# RL6678_IP_SVD register map
Vendor: Realtek
Registers are 32-bit, read-write, reset 0x0 unless marked. A register's access mark holds for its fields unless they carry their own. Offsets are from the block's base; [hi:lo] are bit positions; {n}, {i} and the like mark numbered series.

## LP_SYS
Base 0x42008200
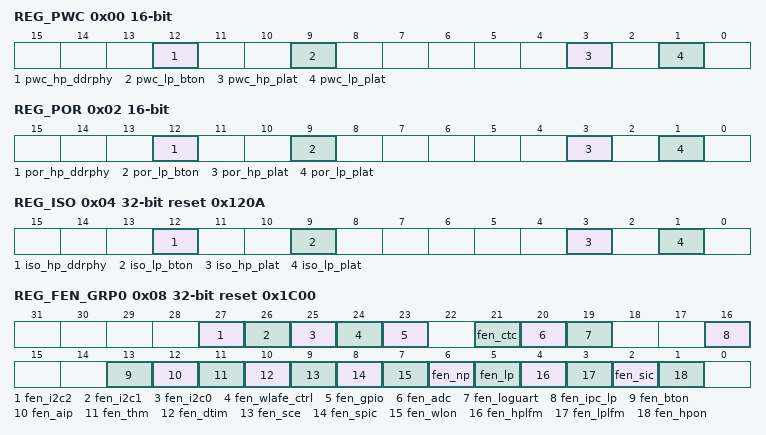
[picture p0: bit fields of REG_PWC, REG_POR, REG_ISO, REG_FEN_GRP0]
0x00 REG_PWC 16-bit
  [12] pwc_hp_ddrphy — 1: Enable ddr phy core power cut 0: Disable
  [9] pwc_lp_bton — This is BT function total power cut control , the BT off power cut is follow it , and is controlled by BT IP . 1: Enable BT power cut 0: Disable
  [3] pwc_hp_plat — This is the default power dommain. 1: Enable HP plat power cut 0: Disable
  [1] pwc_lp_plat — 1: Enable Lp plat power cut 0: Disable
0x02 REG_POR 16-bit
  [12] por_hp_ddrphy — 0: global reset PD_HP_DDRPHY power domain 1: release reset
  [9] por_lp_bton — 0: global reset PD_LP_BTON power domain 1: release por
  [3] por_hp_plat — 0: global reset PD_HP_PLFM power domain 1: release por
  [1] por_lp_plat — 0: global reset PD_LP_PLAT power domain 1: release por
0x04 REG_ISO reset 0x120A
  [12] iso_hp_ddrphy — 1: isolate signals from PD_HP_DDRPHY to other power domain 0: release iso
  [9] iso_lp_bton — 1: isolate signals from PD_LP_BTON to other power domain 0: release iso
  [3] iso_hp_plat — 1: isolate signals from PD_HP_PLFM to other power domain 0: release iso
  [1] iso_lp_plat — 1: isolate signals from PD_LP_PLAT to other power domain 0: release iso
0x08 REG_FEN_GRP0 reset 0x1C00
  [27] fen_i2c2 — 1: enable HS I2C1 function 0: reset
  [26] fen_i2c1 — 1: enable HS I2C0 function 0: reset
  [25] fen_i2c0 — 1: enable LS I2C function 0: reset
  [24] fen_wlafe_ctrl — 1: enable WL RFAFE control circuit, shall be 1 when enable WL or BT use WL RFAFE 0: reset
  [23] fen_gpio — 1: enable LS GPIO function 0: reset
  [21] fen_ctc — 1: enable Captouch ADC function 0: reset
  [20] fen_adc — 1: enable LS ADC function 0: reset
  [19] fen_loguart — Uartlog function reset 1: enable 0: reset
  [16] fen_ipc_lp — 1: enable LS IPC function 0: reset
  [13] fen_bton — BTON function enable 1: enable 0: disable
  [12] fen_aip — Debug thermal function enable
  [11] fen_thm — Debug thermal function enable
  [10] fen_dtim — Debug timer function enable
  [9] fen_sce — Flash sce function enable 1: enable sce 0: disable
  [8] fen_spic — Flash spic function enable 1: enable flash 0: disable flash
  [7] fen_wlon — WLON function enable 1: enable 0: disable
  [6] fen_np — 1: enable KM4 0: reset
  [5] fen_lp — 1: enable KM0 0: reset
  [4] fen_hplfm — 1: enable HP platform 0: reset
  [3] fen_lplfm — 1: enable LP platform 0: reset
  [2] fen_sic — 1: enable SIC function 0: reset
  [1] fen_hpon — 1: enable HS SYSON Function 0: reset
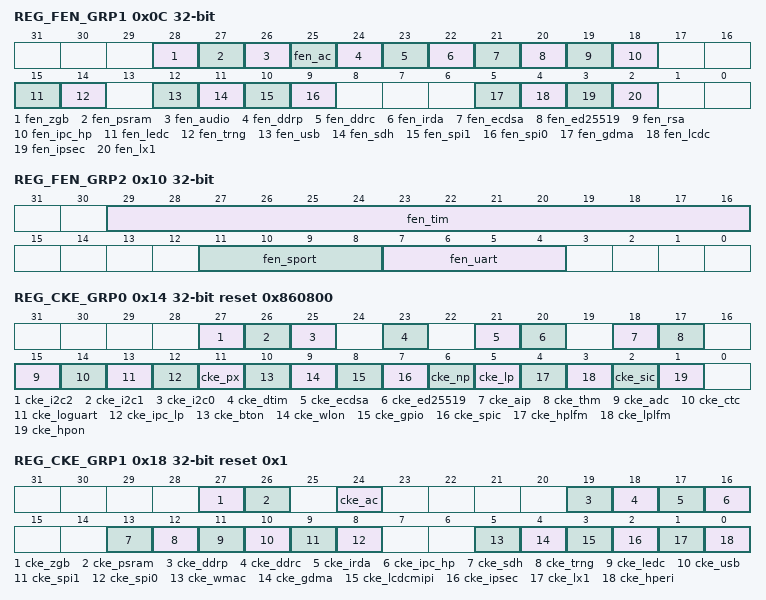
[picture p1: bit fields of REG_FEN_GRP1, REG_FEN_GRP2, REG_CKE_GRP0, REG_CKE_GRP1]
0x0C REG_FEN_GRP1
  [28] fen_zgb — 1: enable zgb function 0: disable Note: for zgb is in wlan off domain , after turn wlan off , it need an 0->1 transiton
  [27] fen_psram — 1: enable PSRAM function 0: disable
  [26] fen_audio — When audio function enable , HS_SYSON_RAM domain must be on , for HSRAM memory at least in retention mode . 1: enable audio function 0: disable
  [25] fen_ac — 1: enable audio codec active function 0: disable
  [24] fen_ddrp — 1: enable ddr phy function 0: disable
  [23] fen_ddrc — 1: enable ddr controller function 0: disable
  [22] fen_irda — 1: enable girda function 0: disable
  [21] fen_ecdsa — 1: enable ecdsa function 0: disable
  [20] fen_ed25519 — 1: enable ed25519 function 0: disable
  [19] fen_rsa — 1: enable rsa function 0: disable
  [18] fen_ipc_hp — 1: enable IPC function 0: disable
  [15] fen_ledc — 1: enable SPORT function 0: disable
  [14] fen_trng — 1: enable TRNG function 0: disable
  [12] fen_usb — 1: enable USB function 0: disable
  [11] fen_sdh — 1: enable SDH function 0: disable
  [10] fen_spi1 — 1: enable SPI1 function 0: disable
  [9] fen_spi0 — 1: enable SPI0 function 0: disable
  [5] fen_gdma — 1: enable GDMA0 function 0: disable
  [4] fen_lcdc — 1: enable LCDC function 0: disable
  [3] fen_ipsec — 1: enable IPSEC function 0: disable
  [2] fen_lx1 — 1: enable LX1 system function 0: disable
0x10 REG_FEN_GRP2
  [29:16] fen_tim — Timer0-13 function enable 0-7 : lp basic timer 8 : pwm timer 9: pulse timer 13-10 : hp basic timer
  [11:8] fen_sport — 1: enable SPORT function 0: disable
  [7:4] fen_uart — Uart function reset (Note uart3 if for BT)
0x14 REG_CKE_GRP0 reset 0x860800
  [27] cke_i2c2 — 1: Enable HS I2C1 clock
  [26] cke_i2c1 — 1: Enable HS I2C0 clock
  [25] cke_i2c0 — 1: Enable LS I2C clock
  [23] cke_dtim — 1: Enable LS dtim clk
  [21] cke_ecdsa — 1: Enable ecdsa engine clock
  [20] cke_ed25519 — 1: Enable ed25519 engine clock
  [18] cke_aip — 1: Enable apb clk for aip use , include xtal/pll/regu control
  [17] cke_thm — 1: Enable LS thm clock
  [15] cke_adc — 1: Enable LS ADC clock
  [14] cke_ctc — 1: Enable Captouch clock
  [13] cke_loguart — 1: Enable Uartlog clock
  [12] cke_ipc_lp — 1: Enable LS IPC clock
  [11] cke_px — 1: Enable Pinmux clock
  [10] cke_bton — 1: Enable BT AON clock
  [9] cke_wlon — 1: Enable WLAN AON clock
  [8] cke_gpio — 1: Enable GPIO clock
  [7] cke_spic — 1: Enable SPIC source clock
  [6] cke_np — 1: Enable KM4 clock
  [5] cke_lp — 1: Enable KM0 clock
  [4] cke_hplfm — 1: Enable hs platform clock
  [3] cke_lplfm — 1: Enable ls platform clock
  [2] cke_sic — 1: Enable SIC clock
  [1] cke_hpon — 1: Enable HSYSON register clock; 0: gated SYSON Register clock
0x18 REG_CKE_GRP1 reset 0x1
  [27] cke_zgb — 1: Enable zgb bus clock 0: Disable
  [26] cke_psram — 1: Enable PSRAM bus clock 0: Disable
  [24] cke_ac — 1: Enable audio codec clock 0: Disable
  [19] cke_ddrp — 1: Enable ddr phy clock 0: Disable
  [18] cke_ddrc — 1: Enable ddrc clock 0: Disable
  [17] cke_irda — 1: Enable irda clock 0: Disable
  [16] cke_ipc_hp — 1: Enable IPC clock 0: Disable
  [13] cke_sdh — 1: Enable SD HOST bus clock 0: Disable
  [12] cke_trng — 1: Enable trng bus clock 0: Disable
  [11] cke_ledc — 1: Enable ledc bus clock 0: Disable
  [10] cke_usb — 1: Enable USB bus clock 0: Disable
  [9] cke_spi1 — 1: Enable SPI1 clock 0: Disable
  [8] cke_spi0 — 1: Enable SPI0 clock 0: Disable
  [5] cke_wmac
  [4] cke_gdma — 1: Enable GDMA0 clock 0: Disable
  [3] cke_lcdcmipi — 1: Enable LCDC&MIPI clock 0: Disable
  [2] cke_ipsec — 1: Enable ipsec clock 0: Disable
  [1] cke_lx1 — 1: Enable lx1 bus clock 0: Disable
  [0] cke_hperi — 1: Enable hperi clock . If IP using hperi clk , this bit must be set . 0: Disable
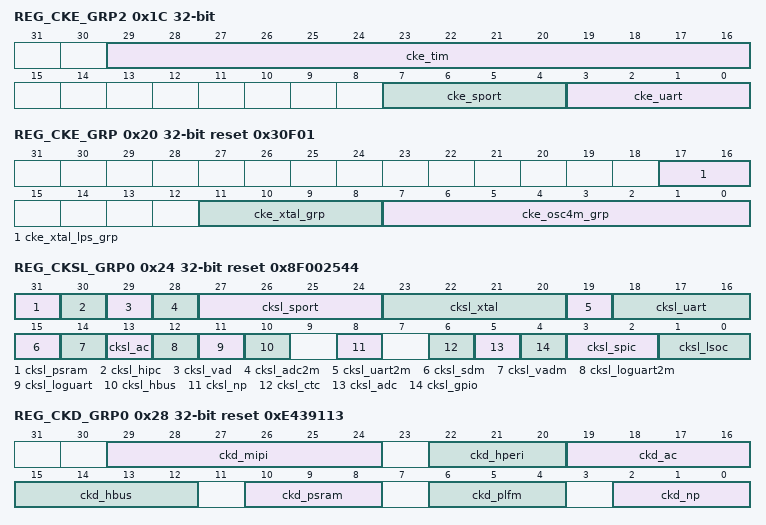
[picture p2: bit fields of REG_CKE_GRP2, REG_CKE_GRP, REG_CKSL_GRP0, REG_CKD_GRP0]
0x1C REG_CKE_GRP2
  [29:16] cke_tim — Timer0-13 clock enable 0-7 : lp basic timer 8 : pwm timer 9: pulse timer 13-10 : hp basic timer
  [7:4] cke_sport — 1: Enable 4path sport clock 0: Disable
  [3:0] cke_uart — 1: Enable Uart1 clock 0: Disable
0x20 REG_CKE_GRP reset 0x30F01
  [17:16] cke_xtal_lps_grp — XTAL lps clock(312.5K) for different use , when neither func used . [0]: system SDM 32K [1]: bt lps clk Note : This field only used for HW debug , software needn't to config it for normal function.
  [11:8] cke_xtal_grp — XTAL 40M clock used for different use , when neither func used [0]: LP system [1]: 40M peri [2]: 2M peri [3]: 40M for NP when xtal is in LPS mode Note : This field only used for HW debug , software needn't to config it for normal function.
  [7:0] cke_osc4m_grp — OSC4M used for different use , when neither func used , osc4m can be disabled . 0: LP system 4M 1: OSC2M peri 2: WL/BT common 3: WL ana clock 4: BT ana clock 5: SDH ana clock 6: aip func control 7: vad Note : This field only used for HW debug , software needn't to config it for normal function. Not use, move to aon reg: cke_osc4m_force
0x24 REG_CKSL_GRP0 reset 0x8F002544
  [31] cksl_psram — psram phy clock seleck 0: xtal 40M 1: nppll divided clock , max to 300M
  [30] cksl_hipc — hs_ipc clock select 0: hapb clk 1: lpon clk(4M)
  [29] cksl_vad — audio codec vad clock select 0: osc4m output 1: xtal 40M divider 10 output . Note : make xtal enter lps mode when vad work to save power
  [28] cksl_adc2m — ADC 2M seleck 0: osc4M divider 2 1: xtal 40M divider out
  [27:24] cksl_sport — sport clock selection 0: equal to audio codec main clock (40M) 1: from I2S pll , after i2s pll selection and divider
  [23:20] cksl_xtal — xtal selection, Default=40MHz 0000: 40MHz 0001: 25MHz 0010: 13MHz 0011: 19.2MHz 0100: 20MHz 0101: 26MHz 0110: 38.4MHz 0111: 17.664MHz 1000: 16MHz 1001: 14.138MHz 1010: 12MHz 1011: 52MHz 1100: 48MHz 1101: 27MHz 1110: 24MHz 1111: none
  [19] cksl_uart2m — Uart 2M seleck 0: osc4M divider 2 1: xtal 40M divider out
  [18:16] cksl_uart — Select uart rx clock for every uart . (Note uart3 is BT uart , always 40M) 0: rx clock is xtal 40M 1: rx clock is 2M (osc2M or xtal divided 2M)
  [15] cksl_sdm — sdm 128 clock select , this must be fixed after initial selection. 0:osc128 1:xtal lps 312.5K
  [14] cksl_vadm — vad share memory clock select . Note, it must first change this bit to 1,and then shutdown hs plfm . When wakeup , it must first enable hs plfm , finally set this bit to 0 . 0: used by hs plfm clock 1: used by vad buffer ctrol
  [13] cksl_ac — audio codec main clock selection 0: syspll divided 40M 1: xtal 40M
  [12] cksl_loguart2m — Loguart 2M seleck 0: osc4M divider 2 1: xtal 40M divider out
  [11] cksl_loguart — Select loguart trx clock 0: clock is xtal 40M 1: clock is 2M
  [10] cksl_hbus — HP bus clock seletion 1: from nppll divider output , which default is 100M 0: from xtal 40M clock
  [8] cksl_np — NP(KM4) clock seletion 1: from nppll divider output , which default is 320M 0: from xtal 40M clock
  [6] cksl_ctc — CTC REG clock selection 0: 131k 1: LS APB Clock
  [5] cksl_adc — ADC INT clock selection 0: LS APB clock 1: OSC2M
  [4] cksl_gpio — GPIO INT clock selecton: 0: LS APB clock 1: 32.768K clock from SDM
  [3:2] cksl_spic — SPIC clock sel: 00/10: OSC4M 01: XTAL 40M 11: nppll divided out,max to 200M
  [1:0] cksl_lsoc — KM0 cpu clock seletion 2'b00/2'b01: ANA4M 2'b10/2'b11: XTAL
0x28 REG_CKD_GRP0 reset 0xE439113
  [29:24] ckd_mipi — mipi vo clock divider, it is based on nppll clock Max timing signoff clock is 66.7M . Default is 800/12 = 66.7 divider by this value + 1
  [22:20] ckd_hperi — audio main clock divider, it is based on np pll output 0~2 : not valid 3: div4 4: div5 other: divider by this value + 1
  [19:16] ckd_ac — audio main clock divider, it is based on np pll output 0~2 : not valid 3: div20 4: div21 other: divider by this value + 17
  [15:12] ckd_hbus — ahb clock divider, it is based on np pll output 0~6 : not valid 7: div8 8: div9 other: divider by this value + 1
  [10:8] ckd_psram — PSRAM phy clock divider, it is based on np pll (600M). 0: not valid 1: div2 2: div3 3/other: divider by this value + 1
  [6:4] ckd_plfm — PLFM clock divider, it is based on np clock . 0: not valid 1: div2 (it is better to fix in this value) 2: div3 3/other: divider by this value + 1
  [2:0] ckd_np — NP clock divider, it is based on np pll (800M). 0: not valid 1: div2 2: div3 3/other: divider by this value + 1
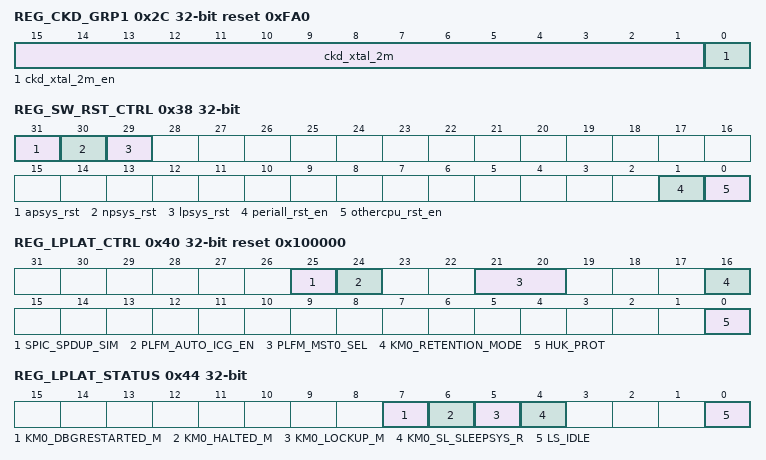
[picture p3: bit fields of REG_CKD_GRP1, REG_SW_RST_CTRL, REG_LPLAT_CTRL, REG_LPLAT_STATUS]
0x2C REG_CKD_GRP1 reset 0xFA0
  [15:1] ckd_xtal_2m — Output divided clock frequency for UART: BIT_LSYS_UART_XTAL_DIV_FREQ/1000 (MHz)
  [0] ckd_xtal_2m_en — 1: enable XTAL division circuit for UART
0x38 REG_SW_RST_CTRL
  [31] apsys_rst — Only when REG_SW_RST_TRIG is 0x69696969 , this reg can be write
  [30] npsys_rst — Only when REG_SW_RST_TRIG is 0x69696969 , this reg can be write
  [29] lpsys_rst — Only when REG_SW_RST_TRIG is 0x69696969 , this reg can be write
  [1] periall_rst_en — 1. warm reset request by one cpu will reset all peri and local cpu 0. warm reset request by one cpu will only reset local cpu Note : peri rst will use sysrst mst also
  [0] othercpu_rst_en — 1. warm reset request by one cpu will reset other cpu's core and local cpu 0. warm reset request by one cpu will only reset local cpu
0x3C REG_SW_RST_TRIG
  [31:0] trig_rst — System reset trigger register Write 0x96969696 to enable the write of reset control Write 0x69696969 will trigger the system if REG_SW_RST_CTRL set .
0x40 REG_LPLAT_CTRL reset 0x100000
  [25] SPIC_SPDUP_SIM — 1: SPIC will wait 256 spic_clk cycles before ready 0: SPIC will wait 2^16 spic_clk cycles before ready
  [24] PLFM_AUTO_ICG_EN — 1: Enable LS platform auto clock-gating for power save 0: Disable
  [21:20] PLFM_MST0_SEL — LS platfrom m0 select 0: SIC 1: OTPC 2/3: KM0 Default is OTPC for autoload , after done , pmc will set thi field to KM0 , or SIC(testmode)
  [16] KM0_RETENTION_MODE — 1: Enable, when KM0 reset, Cache will not be cleared 0: Disable, when KM0 reset, Cache will be cleared by HW
  [0] HUK_PROT — 0: only cpu can read HUK key 1: no one can read HUK key This bit will be latch to high when it was write to 1 until reset again .
0x44 REG_LPLAT_STATUS ro
  [7] KM0_DBGRESTARTED_M — KM0 debug restart status
  [6] KM0_HALTED_M — KM0 halt status
  [5] KM0_LOCKUP_M — KM0 lockup status
  [4] KM0_SL_SLEEPSYS_R — KM0 sleep status
  [0] LS_IDLE — Indicate LS plfm is in IDLE state , thus can change m0_select
0x48 REG_SW_PATCH reset 0x23008000
  [31:0] sw_patch_saddr — SW patch code start addr. OTP physical addr 0x500-0x6FF will autoload to this addr .
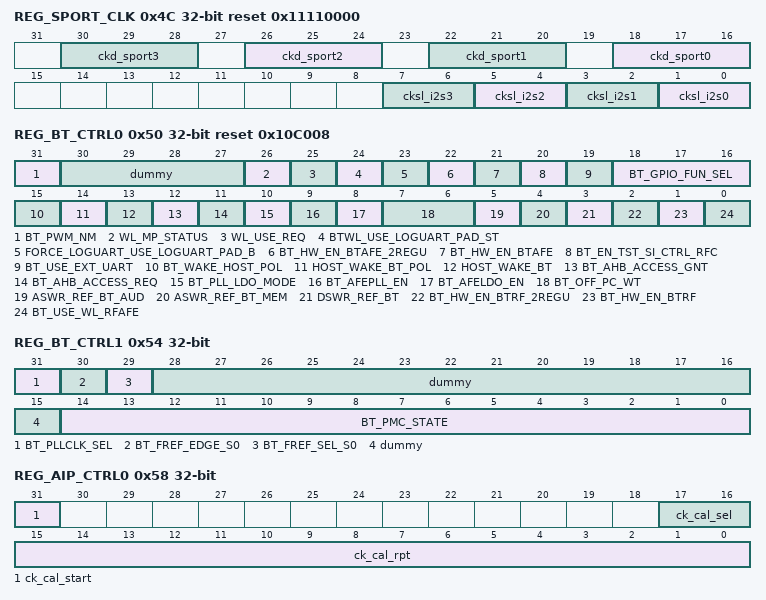
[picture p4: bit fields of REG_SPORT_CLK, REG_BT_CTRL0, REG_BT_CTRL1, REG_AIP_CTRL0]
0x4C REG_SPORT_CLK reset 0x11110000
  [4n+18:4n+16] ckd_sport{n} (n=0..3) — Sport clock divider, it is based on np i2s1 pll and i2s2 pll mux out 0: not valid 1: div2 2: div3 3/other: divider by this value + 1
  [2n+1:2n] cksl_i2s{n} (n=0..3) — I2S pll selection for sport{n} 10: select i2s pll1 which is 98.304M 01: select i2s pll2 which is 45.158M 11: select i2s pll1 which is 24.576M 00: reserved
0x50 REG_BT_CTRL0 access per field reset 0x10C008
  [31] BT_PWM_NM rw — ECO Add. SWR mode of BT active 1: PWM Mode 0: PFM Mode
  [30:27] dummy rw — HW used only , these are for reserved.
  [26] WL_MP_STATUS rw — Wi-Fi MP status
  [25] WL_USE_REQ rw — who uses loguart trx pad depends on the xor of WL_USE_REQ and BT_USE_REQ, wifi can send use request by change the value of WL_USE_REQ
  [24] BTWL_USE_LOGUART_PAD_ST ro — The state of xor of WL_USE_REQ and BT_USE_REQ. 0: loguart use loguart trx pad 1: bt hci use loguart trx pad
  [23] FORCE_LOGUART_USE_LOGUART_PAD_B rw — Force wifi soc to use loguart pad mandatory if necessary 0: loguart use loguart trx pad 1: who uses loguart trx pad depends on BTWL_USE_LOGUART_PAD_ST
  [22] BT_HW_EN_BTAFE_2REGU rw — Control 3.3V power reset of BT afe, need level shift to 3.3V by regu, SW shall set the bit to1 when BT use BT AFE
  [21] BT_HW_EN_BTAFE rw — Core power reset of BT afe, SW shall set the bit to1 when BT use BT AFE
  [20] BT_EN_TST_SI_CTRL_RFC rw
  [19] BT_USE_EXT_UART rw — 1: BT use external uart 0: BT use internal uart
  [18:16] BT_GPIO_FUN_SEL rw — BT GPIO function select, 5:I2C mode
  [15] BT_WAKE_HOST_POL rw — 1: BT_WAKE_HOST to CPU and pinmux 0: pinmux to CPU for external trig
  [14] HOST_WAKE_BT_POL rw — 1: HOST_WAKE_BT to BT and pinmux 0: pinmux to BT for external trig
  [13] HOST_WAKE_BT rw — CPU set this bit to 1 to wake BT
  [12] BT_AHB_ACCESS_GNT ro — Access grant for system master access BT reg through AHB bus
  [11] BT_AHB_ACCESS_REQ rw — System master set this bit to 1 and wait BT_AHB_ACCESS_GNT=1 before access BT reg through AHB bus, when access finish, shall set this bit to 0
  [10] BT_PLL_LDO_MODE rw — 1: system force AFE PLL LDO to Power cut mode 0: AFE PLL LDO mode is controlled by BTON parameter
  [9] BT_AFEPLL_EN rw — 1: system force AFE PLL enable 0: AFE PLL enable by BT PMC
  [8] BT_AFELDO_EN rw — 1: system force AFE LDO enable 0: AFE LDO enable by BT PMC
  [7:6] BT_OFF_PC_WT rw — Wait time select for BT off power cut stable
  [5] ASWR_REF_BT_AUD rw — Audio swr parameter refer BT status
  [4] ASWR_REF_BT_MEM rw — Memory swr parameter refer BT status
  [3] DSWR_REF_BT rw — Core swr parameter refer BT status
  [2] BT_HW_EN_BTRF_2REGU rw — Control 3.3V power reset of BT rfc, need level shift to 3.3V by regu, SW shall set the bit to1 when BT use BT RFC
  [1] BT_HW_EN_BTRF rw — Core power reset of BT rfc, SW shall set the bit to1 when BT use BT RFC
  [0] BT_USE_WL_RFAFE rw — Indicate BT select WL RFAFE, shall not switch when BT is on
0x54 REG_BT_CTRL1 access per field
  [31] BT_PLLCLK_SEL rw — ECO ADD 0: select BTS0_ANAPAR_PLL0[10]&[4] from BT 1: select from REG 0x54[30:29]
  [30] BT_FREF_EDGE_S0 rw — ECO ADD BTS0_ANAPAR_PLL0[10]. Valid when 0x54[31] = 1
  [29] BT_FREF_SEL_S0 rw — ECO ADD BTS0_ANAPAR_PLL0[4]. Valid when 0x54[31] = 1
  [28:15] dummy rw — HW used only , these are for reserved.
  [14:0] BT_PMC_STATE ro — Indicate BT PMC current state, for debug
0x58 REG_AIP_CTRL0 access per field
  [31] ck_cal_start rw — Start clk calibration . This bit will auto-set to 0 when cal done .
  [17:16] ck_cal_sel rw — Calibration clock selection . The refrence clock is xtal clock. 0: OSC4M 1: AON100K 2: AON128K for SDM
  [15:0] ck_cal_rpt ro — Clock calibration result
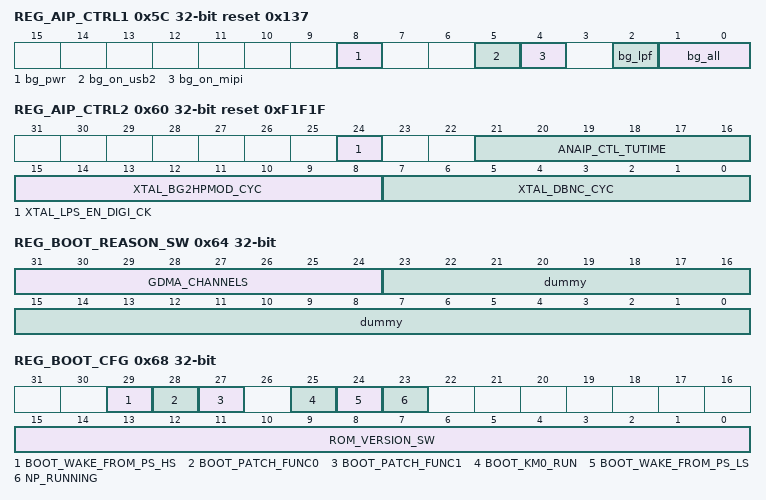
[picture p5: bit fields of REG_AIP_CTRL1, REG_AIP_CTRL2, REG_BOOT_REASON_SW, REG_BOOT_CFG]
0x5C REG_AIP_CTRL1 reset 0x137
  [8] bg_pwr — 1: power on ddrphy bandgap 0: shutdown bg
  [5] bg_on_usb2 — Bandgap USB2 current enable
  [4] bg_on_mipi — Bandgap MIPI current enable
  [2] bg_lpf — Bandgap low pass filter
  [1:0] bg_all — Bandgap enable mode
0x60 REG_AIP_CTRL2 reset 0xF1F1F
  [24] XTAL_LPS_EN_DIGI_CK — 0: disable XTAL clock for digital when XTAL enter LPS mode 1: enable XTAL clock for digital when XTAL enter LPS mode
  [21:16] ANAIP_CTL_TUTIME — Timeunit of SWR/XTAL arbitration circuit, in unit of ANA4M, Default time unit: 4us
  [15:8] XTAL_BG2HPMOD_CYC — The time interval between BG enable to XTAL switch to HP Mode, the timeunit is control by 0x13C[21:16]: BIT_LSYS_ANAIP_CTL_TUTIME
  [7:0] XTAL_DBNC_CYC — De-bounce time of XTAL enable request from WIFI & SYSON PMC, the timeunit is control by 0x13C[21:16]: BIT_LSYS_ANAIP_CTL_TUTIME
0x64 REG_BOOT_REASON_SW
  [31:24] GDMA_CHANNELS — Indicate the usage status of every GDMA channel.
  [23:0] dummy
0x68 REG_BOOT_CFG
  [29] BOOT_WAKE_FROM_PS_HS, [28] BOOT_PATCH_FUNC0, [27] BOOT_PATCH_FUNC1, [25] BOOT_KM0_RUN, [24] BOOT_WAKE_FROM_PS_LS, [23] NP_RUNNING, [15:0] ROM_VERSION_SW
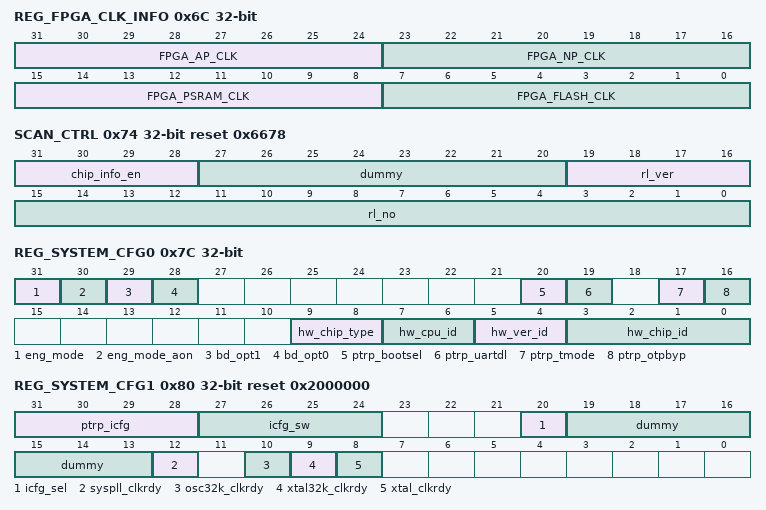
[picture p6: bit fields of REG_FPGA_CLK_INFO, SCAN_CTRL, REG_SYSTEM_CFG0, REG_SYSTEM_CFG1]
0x6C REG_FPGA_CLK_INFO ro
  [31:24] FPGA_AP_CLK — FPGA AP clock
  [23:16] FPGA_NP_CLK — FPGA NP clock
  [15:8] FPGA_PSRAM_CLK — FPGA PSRAM clock
  [7:0] FPGA_FLASH_CLK — FPGA Flash clock
0x70 REG_FLASH_PARA_ADDR
  [31:0] dummy
0x74 SCAN_CTRL access per field reset 0x6678
  [31:28] chip_info_en rw — Only when this field set to 4'hA, rl_ver/rl_no can be read out .
  [27:20] dummy rw — HW used only , these are for reserved.
  [19:16] rl_ver ro — CHIP cut verison : 0: A-cut 1: B-cut ...
  [15:0] rl_no ro — CHIP RL NUMBER : 0x6678
0x7C REG_SYSTEM_CFG0 access per field
  [31] eng_mode ro — Indicate PKG_ENG_SEL pad value 0: normal package; 1: engineering mode
  [30] eng_mode_aon rw — Wrtie 1 to set aon enter eng_mode
  [29] bd_opt1 ro — Bonding option-ext_clk
  [28] bd_opt0 ro — Bonding option-ext_rstb
  [20] ptrp_bootsel ro — Power on trapped bootsel value
  [19] ptrp_uartdl ro — Power on trapped uart download value 0: Normal boot 1: uartdownload boot TODO: it may be overwrited by efuse autoload
  [17] ptrp_tmode ro — 0: normal mode 1: test mode
  [16] ptrp_otpbyp ro — 1: force efuse autoload fail
  [9:8] hw_chip_type ro — Chip type 00: ASIC 01: FPGA 10: PALADIUM 11: RTL_SIM
  [7:6] hw_cpu_id ro — Different CPU reading this register will return different value. If read by LP: return 0 If read by NP: return 1 if read by AP: return 2
  [5:4] hw_ver_id ro — Vendor ID Download FW version 00: UMC 01: SMIC 10: TSMC
  [3:0] hw_chip_id ro — Chip ID 0000: A-cut 0001: B-cut 0010: C-cut 0011: D-cut ...
0x80 REG_SYSTEM_CFG1 access per field reset 0x2000000
  [31:28] ptrp_icfg ro — Trapped ICFG data value 0: normall mode XXXX: the other mode (Test Mode)
  [27:24] icfg_sw rw — Using soft virtual icfg in follow case : 1. icfg_sel is 1,if set icfg_sw = 0 , it will force to normal mode 2. testmode and icfg_sel is 0 and ptrp_icfg is 0
  [20] icfg_sel rw — If 1, using icfg_sw to replace trapped icfg value.
  [19:13] dummy rw
  [12] syspll_clkrdy ro — System pll ready flag 1: ready
  [10] osc32k_clkrdy ro — OSC 128k ready flag 1: ready
  [9] xtal32k_clkrdy ro — XTAL 32k ready flag 1: ready
  [8] xtal_clkrdy ro — XTAL clock stable 1: Clock Stable
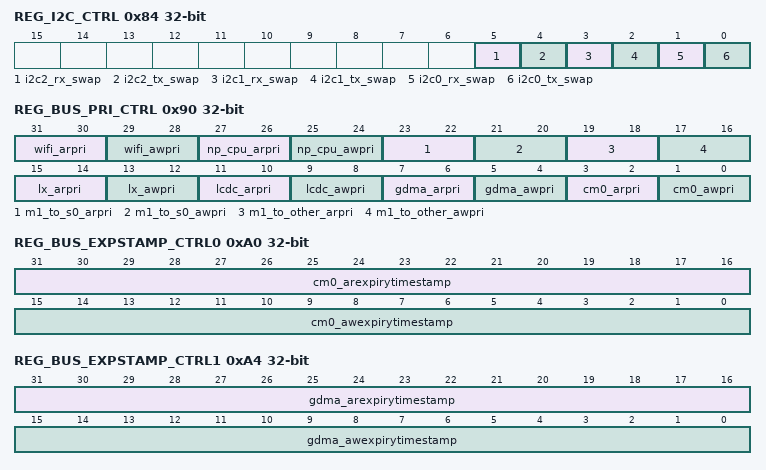
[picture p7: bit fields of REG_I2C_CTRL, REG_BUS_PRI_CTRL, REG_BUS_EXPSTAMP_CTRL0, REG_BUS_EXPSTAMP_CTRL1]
0x84 REG_I2C_CTRL
  [5] i2c2_rx_swap — I2C2 RX swap control
  [4] i2c2_tx_swap — I2C2 TX swap control
  [3] i2c1_rx_swap — I2C1 RX swap control
  [2] i2c1_tx_swap — I2C1 TX swap control
  [1] i2c0_rx_swap — I2C0 RX swap control
  [0] i2c0_tx_swap — I2C0 TX swap control
0x90 REG_BUS_PRI_CTRL
  [31:30] wifi_arpri — Wlan read pri control
  [29:28] wifi_awpri — Wlan write pri control
  [27:26] np_cpu_arpri — np cpu read pri control
  [25:24] np_cpu_awpri — np cpu write pri control
  [23:22] m1_to_s0_arpri — m1 to sys read pri control
  [21:20] m1_to_s0_awpri — m1 to sys write pri control
  [19:18] m1_to_other_arpri — m1 to other read pri control
  [17:16] m1_to_other_awpri — m1 to other write pri control
  [15:14] lx_arpri — lx read pri control
  [13:12] lx_awpri — lx write pri control
  [11:10] lcdc_arpri — LCDC read pri control
  [9:8] lcdc_awpri — LCDC write pri control
  [7:6] gdma_arpri — GDMA read pri control
  [5:4] gdma_awpri — GDMA write pri control
  [3:2] cm0_arpri — LS CM0 read pri control
  [1:0] cm0_awpri — LS CM0 write pri control
0xA0 REG_BUS_EXPSTAMP_CTRL0
  [31:16] cm0_arexpirytimestamp — ls cm0 read expirytimestamp control
  [15:0] cm0_awexpirytimestamp — ls cm0 write expirytimestamp control
0xA4 REG_BUS_EXPSTAMP_CTRL1
  [31:16] gdma_arexpirytimestamp — gdma read expirytimestamp control
  [15:0] gdma_awexpirytimestamp — gdma write expirytimestamp control
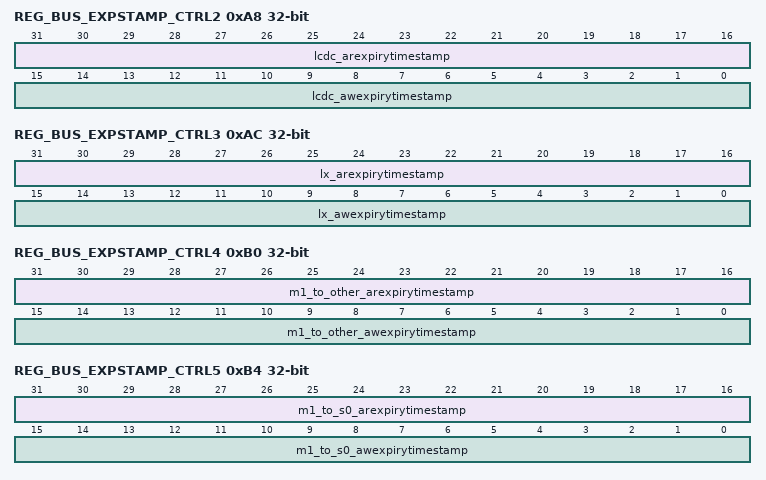
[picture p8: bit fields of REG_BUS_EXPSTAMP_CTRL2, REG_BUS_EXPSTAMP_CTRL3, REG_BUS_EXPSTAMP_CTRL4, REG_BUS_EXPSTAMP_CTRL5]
0xA8 REG_BUS_EXPSTAMP_CTRL2
  [31:16] lcdc_arexpirytimestamp — lcdc read expirytimestamp control
  [15:0] lcdc_awexpirytimestamp — lcdc write expirytimestamp control
0xAC REG_BUS_EXPSTAMP_CTRL3
  [31:16] lx_arexpirytimestamp — lx read expirytimestamp control
  [15:0] lx_awexpirytimestamp — lx write expirytimestamp control
0xB0 REG_BUS_EXPSTAMP_CTRL4
  [31:16] m1_to_other_arexpirytimestamp — m1 to other read expirytimestamp control
  [15:0] m1_to_other_awexpirytimestamp — m1 to other write expirytimestamp control
0xB4 REG_BUS_EXPSTAMP_CTRL5
  [31:16] m1_to_s0_arexpirytimestamp — m1 to sys read expirytimestamp control
  [15:0] m1_to_s0_awexpirytimestamp — m1 to sys write expirytimestamp control
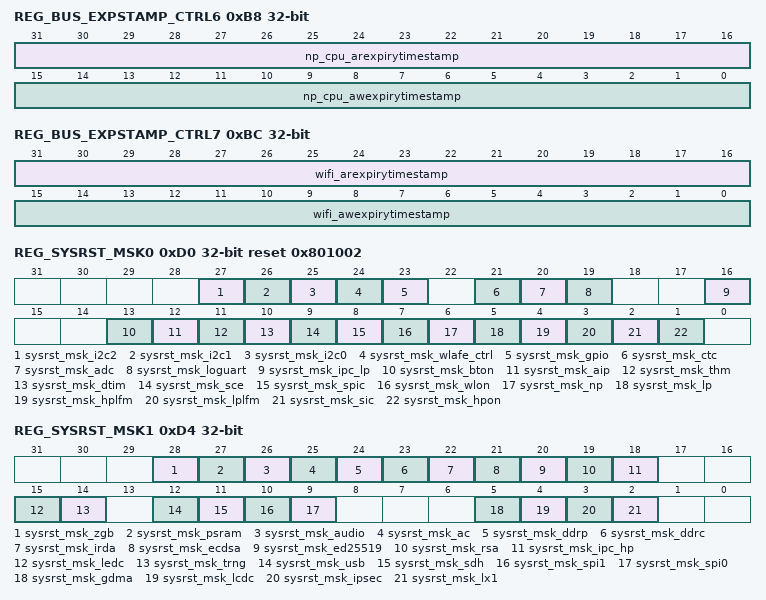
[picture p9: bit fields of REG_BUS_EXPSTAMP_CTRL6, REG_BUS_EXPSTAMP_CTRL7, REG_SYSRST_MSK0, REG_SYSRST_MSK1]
0xB8 REG_BUS_EXPSTAMP_CTRL6
  [31:16] np_cpu_arexpirytimestamp — np cpu read expirytimestamp control
  [15:0] np_cpu_awexpirytimestamp — np cpu write expirytimestamp control
0xBC REG_BUS_EXPSTAMP_CTRL7
  [31:16] wifi_arexpirytimestamp — wlan read expirytimestamp control
  [15:0] wifi_awexpirytimestamp — wlan write expirytimestamp control
0xC0 REG_DUMMY_088 reset 0xFFFFFFFF
  [31:0] dummy — HW used only , these are for reserved.
0xC4 REG_DUMMY_089
  [31:0] dummy — HW used only , these are for reserved.
0xD0 REG_SYSRST_MSK0 reset 0x801002
  [27] sysrst_msk_i2c2 — 1: mask HS I2C1 reset when sys reset happen 0: reset
  [26] sysrst_msk_i2c1 — 1: mask HS I2C0 reset when sys reset happen 0: reset
  [25] sysrst_msk_i2c0 — 1: mask LS I2C reset when sys reset happen 0: reset
  [24] sysrst_msk_wlafe_ctrl — 1: mask WL RFAFE control circuit, shall be 1 when mask WL or BT use WL RFAFE 0: reset
  [23] sysrst_msk_gpio — 1: mask LS GPIO reset when sys reset happen 0: reset
  [21] sysrst_msk_ctc — 1: mask Captouch ADC reset when sys reset happen 0: reset
  [20] sysrst_msk_adc — 1: mask LS ADC reset when sys reset happen 0: reset
  [19] sysrst_msk_loguart — mask reset when sys reset happen reset 1: mask 0: reset
  [16] sysrst_msk_ipc_lp — 1: mask LS IPC reset when sys reset happen 0: reset
  [13] sysrst_msk_bton — mask reset when sys reset happen mask 1: mask 0: disable
  [12] sysrst_msk_aip — mask aip reset when sys reset happen mask
  [11] sysrst_msk_thm — mask thml reset when sys reset happen mask
  [10] sysrst_msk_dtim — mask dtim reset when sys reset happen mask
  [9] sysrst_msk_sce — mask rsip reset when sys reset happen mask 1: mask sce 0: disable
  [8] sysrst_msk_spic — mask Flash spic reset when sys reset happen mask 1: mask flash 0: disable flash
  [7] sysrst_msk_wlon — mask WLON reset when sys reset happen mask 1: mask 0: disable
  [6] sysrst_msk_np — 1: mask KM4 0: reset
  [5] sysrst_msk_lp — 1: mask KM0 0: reset
  [4] sysrst_msk_hplfm — 1: mask HP platform 0: reset
  [3] sysrst_msk_lplfm — 1: mask LP platform 0: reset
  [2] sysrst_msk_sic — 1: mask SIC reset when sys reset happen 0: reset
  [1] sysrst_msk_hpon — 1: mask HS SYSON reset when sys reset happen 0: reset
0xD4 REG_SYSRST_MSK1
  [28] sysrst_msk_zgb — 1: mask zgb reset when sys reset happen 0: disable Note: for zgb is in wlan off domain , after turn wlan off , it need an 0->1 transiton
  [27] sysrst_msk_psram — 1: mask PSRAM reset when sys reset happen 0: disable
  [26] sysrst_msk_audio — When audio reset when sys reset happen mask , HS_SYSON_RAM domain must be on , for HSRAM memory at least in retention mode . 1: mask audio reset when sys reset happen 0: disable
  [25] sysrst_msk_ac — 1: mask audio codec active reset when sys reset happen 0: disable
  [24] sysrst_msk_ddrp — 1: mask ddr phy reset when sys reset happen 0: disable
  [23] sysrst_msk_ddrc — 1: mask ddr controller reset when sys reset happen 0: disable
  [22] sysrst_msk_irda — 1: mask girda reset when sys reset happen 0: disable
  [21] sysrst_msk_ecdsa — 1: mask ecdsa reset when sys reset happen 0: disable
  [20] sysrst_msk_ed25519 — 1: mask ed25519 reset when sys reset happen 0: disable
  [19] sysrst_msk_rsa — 1: mask rsa reset when sys reset happen 0: disable
  [18] sysrst_msk_ipc_hp — 1: mask IPC reset when sys reset happen 0: disable
  [15] sysrst_msk_ledc — 1: mask SPORT reset when sys reset happen 0: disable
  [14] sysrst_msk_trng — 1: mask TRNG reset when sys reset happen 0: disable
  [12] sysrst_msk_usb — 1: mask USB reset when sys reset happen 0: disable
  [11] sysrst_msk_sdh — 1: mask SDH reset when sys reset happen 0: disable
  [10] sysrst_msk_spi1 — 1: mask SPI1 reset when sys reset happen 0: disable
  [9] sysrst_msk_spi0 — 1: mask SPI0 reset when sys reset happen 0: disable
  [5] sysrst_msk_gdma — 1: mask GDMA0 reset when sys reset happen 0: disable
  [4] sysrst_msk_lcdc — 1: mask LCDC reset when sys reset happen 0: disable
  [3] sysrst_msk_ipsec — 1: mask IPSEC reset when sys reset happen 0: disable
  [2] sysrst_msk_lx1 — 1: mask LX1 system reset when sys reset happen 0: disable
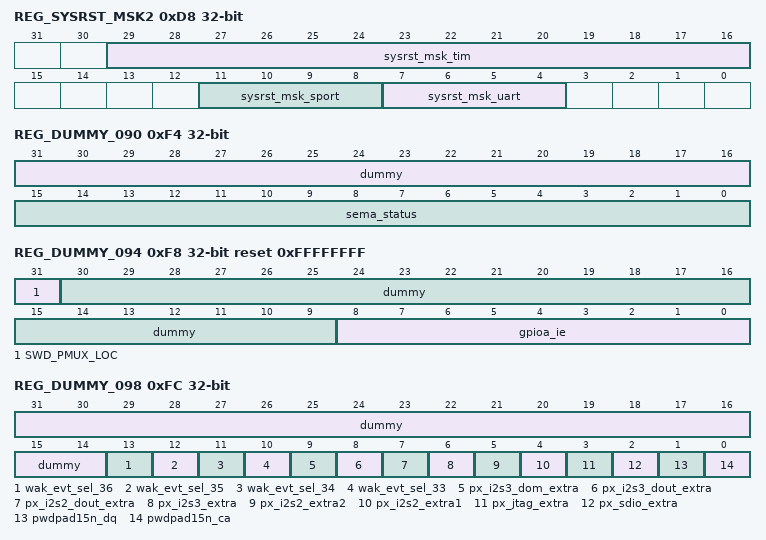
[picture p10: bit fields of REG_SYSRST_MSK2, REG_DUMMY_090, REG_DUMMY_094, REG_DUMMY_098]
0xD8 REG_SYSRST_MSK2
  [29:16] sysrst_msk_tim — mask Timer0-7 reset when sys reset happen mask
  [11:8] sysrst_msk_sport — 1: mask SPORT reset when sys reset happen 0: disable
  [7:4] sysrst_msk_uart — Uart reset when sys reset happen reset (Note uart3 if for BT)
0xF0 REG_BOUNDARY_CHK reset 0xBDC10512
  [31:0] dummy — HW used only , Used for access boundary check, SYSON is 512B which is 000-1FF.
0xF4 REG_DUMMY_090 access per field
  [31:16] dummy rw — HW used only , these are for reserved. [15:0]: used as 16bit semaphore
  [15:0] sema_status ro — Dcut ECO : semaphare status bits
0xF8 REG_DUMMY_094 reset 0xFFFFFFFF
  [31] SWD_PMUX_LOC — Dcut ECO : swd px location selection 1: default as ccut , swd locate at PA13/PA14 0: swd locate at PB25/PB26 Note : Location valid only when SWD_PMUX_EN = 1(pad reg : 0x4200_8BF8[0]) to disable SWD PX function , only set SWD_PMUX_EN = 0
  [30:9] dummy — HW used only , these are for reserved.
  [8:0] gpioa_ie — ECO: GPIOA input enable
0xFC REG_DUMMY_098
  [31:14] dummy — HW used only , these are for reserved.
  [13] wak_evt_sel_36
  [12] wak_evt_sel_35
  [11] wak_evt_sel_34
  [10] wak_evt_sel_33 — dcut ECO : 0: as CCUT , wak_evt[36:33] select to wdg_evt 1: wak_evt[36:33] select to hs_tim13-10
  [9] px_i2s3_dom_extra — dcut ECO : i2s3 din extra fid
  [8] px_i2s3_dout_extra — dcut ECO : i2s3 dout extra fid
  [7] px_i2s2_dout_extra — dcut ECO : i2s2 dout extra fid
  [6] px_i2s3_extra — dcut ECO : i2s3 extra fid
  [5] px_i2s2_extra2 — dcut ECO : i2s2 extra2 fid
  [4] px_i2s2_extra1 — dcut ECO : i2s2 extra1 fid
  [3] px_jtag_extra — dcut ECO : i2s3 extra fid
  [2] px_sdio_extra — dcut ECO : sdio extra fid
  [1] pwdpad15n_dq — ECO: control DDRPHY DQ pad power down 0: power down 1: enable Before DDRPHY ready , this bit must set 1 to iso DRAM Note: DQ pad is shared as psram
  [0] pwdpad15n_ca — ECO: control DDRPHY CA pad power down 0: power down 1: enable Before DDRPHY ready , this bit must set 1 to iso DRAM
